# SN32F290 register map
Vendor: SONIX; File version: 2026.10.03
CPU: CM0 r0p0, little endian, 2 interrupt priority bits
Registers are 32-bit, read-write, reset 0x0 unless marked. A register's access mark holds for its fields unless they carry their own. Offsets are from the block's base; [hi:lo] are bit positions; {n}, {i} and the like mark numbered series; 'fields as' and 'values as' point back to an identical list.

## SN_EBI — External Bus Interface
Base 0x40036000
0x00 CTRL reset 0xF00000 (reset mask 0xFFFFFFF) — Offset:0x0 EBI Control Register
  [2n+48:n+24] BK8080MODE{n} (n=0..3) — Bank{n} 8080 Mode
    0=A1D16 (A1D16 mode); 1=A1D8 (A1D8 mode)
  [43:20] IDLETIME — Bus idle time
    0=No (No Idle time); {v}={v}T (Idle time={v}*PCLK) (v=1..15)
  [2n+32:n+16] ARDY{n}EN (n=0..3) — ARDY of bank {n} enable bit
    0=Disable bank {n} ARDY function; 1=Enable bank {n} ARDY function
  [2n+24:n+12] BC{n}EN (n=0..3) — Byte control of bank {n} enable bit
    0=Disable byte control of bank {n}; 1=Enable byte control of bank {n}
  [2n+16:n+8] BANK{n}EN (n=0..3) — EBI bank {n} enable bit
    0=Disable bank {n}; 1=Enable bank {n}
  [4n+1:2n] MODE{n} (n=0..3) — EBI bank {n} access mode
    0=AnD8 mode; 1=AnD16 mode; 2=AnD16ALE mode; 3=8080 mode
0x04 ALCTRL (reset mask 0xFFFF) — Offset:0x4 EBI Address Latch Control Register
  [8n+3:4n] AL{n} (n=0..3) — Bank {n} address length=AL{n}+16
    0=0000b (AL{n}=0); 1=0001b (AL{n}=1); 10=1010b (AL{n}=10); 11=1011b (AL{n}=10); 12=1100b (AL{n}=10); 13=1101b (AL{n}=10); 14=1110b (AL{n}=10); 15=1111b (AL{n}=10); 2=0010b (AL{n}=2); 3=0011b (AL{n}=3); 4=0100b (AL{n}=4); 5=0101b (AL{n}=5); 6=0110b (AL{n}=6); 7=0111b (AL{n}=7); 8=1000b (AL{n}=8); 9=1001b (AL{n}=9)
0x08 STATUS reset 0x10 (reset mask 0x111) — Offset:0x8 EBI Status Register
  [16:8] EBINSRST — EBI State machine reset
    0=Normal mode; 1=Reset EBI state machine
  [8:4] EBIARDY ro — EBI Asynchronous Ready status
    0=Inactive (EBI_ARDY is inactive); 1=Active (EBI_ARDY is active)
  [0] EBIBUSY ro
    0=Idle (EBI is idle); 1=Busy (EBI is busy)
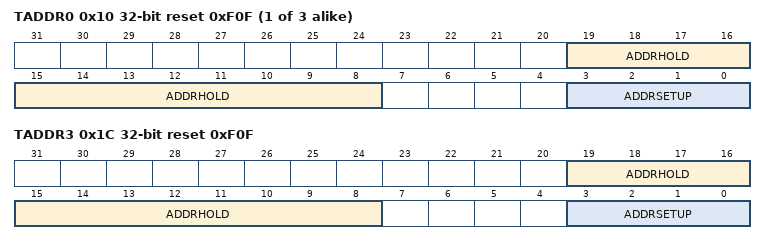
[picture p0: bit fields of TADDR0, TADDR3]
{0x10+4i} TADDR{i} reset 0xF0F (reset mask 0xF0F) (i=0..2) — Offset:{0x10+4i} EBI Address Timing Register {i}
  [19:8] ADDRHOLD — Address Hold time
    0=0000b (No Hold time); 1=0001b (1*PCLK); 10=1010b (10*PCLK); 11=1011b (11*PCLK); 12=1100b (12*PCLK); 13=1101b (13*PCLK); 14=1110b (14*PCLK); 15=1111b (15*PCLK); 2=0010b (2*PCLK); 3=0011b (3*PCLK); 4=0100b (4*PCLK); 5=0101b (5*PCLK); 6=0110b (6*PCLK); 7=0111b (7*PCLK); 8=1000b (8*PCLK); 9=1001b (9*PCLK)
  [3:0] ADDRSETUP — Address Setup time
    0=0000b (1*PCLK); 1=0001b (1*PCLK); 10=1010b (10*PCLK); 11=1011b (11*PCLK); 12=1100b (12*PCLK); 13=1101b (13*PCLK); 14=1110b (14*PCLK); 15=1111b (15*PCLK); 2=0010b (2*PCLK); 3=0011b (3*PCLK); 4=0100b (4*PCLK); 5=0101b (5*PCLK); 6=0110b (6*PCLK); 7=0111b (7*PCLK); 8=1000b (8*PCLK); 9=1001b (9*PCLK)
0x1C TADDR3 reset 0xF0F (reset mask 0xF0F) — Offset:0x1C EBI Address Timing Register 3
  [19:8] ADDRHOLD — Address Hold time
    0=0000b (No address hold time); 1=0001b (1*PCLK); 10=1010b (10*PCLK); 11=1011b (11*PCLK); 12=1100b (12*PCLK); 13=1101b (13*PCLK); 14=1110b (14*PCLK); 15=1111b (15*PCLK); 2=0010b (2*PCLK); 3=0011b (3*PCLK); 4=0100b (4*PCLK); 5=0101b (5*PCLK); 6=0110b (6*PCLK); 7=0111b (7*PCLK); 8=1000b (8*PCLK); 9=1001b (9*PCLK)
  [3:0] ADDRSETUP — Address Setup time
    values as TADDR0.ADDRSETUP
{0x20+4i} TREAD{i} reset 0xF3F0F (reset mask 0xF3F0F) (i=0..3) — Offset:{0x20+4i} EBI Read Timing Register {i}
  [35:16] RDHOLD — Read Hold time
    0=0000b (No read hold time); 1=0001b (1*PCLK); 10=1010b (10*PCLK); 11=1011b (11*PCLK); 12=1100b (12*PCLK); 13=1101b (13*PCLK); 14=1110b (14*PCLK); 15=1111b (15*PCLK); 2=0010b (2*PCLK); 3=0011b (3*PCLK); 4=0100b (4*PCLK); 5=0101b (5*PCLK); 6=0110b (6*PCLK); 7=0111b (7*PCLK); 8=1000b (8*PCLK); 9=1001b (9*PCLK)
  [21:8] RDSTRB — Read Strobe time
    0=000000b (1*PCLK); 1=000001b (1*PCLK); 10=001010b (10*PCLK); 11=001011b (11*PCLK); 12=001100b (12*PCLK); 13=001101b (13*PCLK); 14=001110b (14*PCLK); 15=001111b (15*PCLK); 16=010000b (16*PCLK); 17=010001b (17*PCLK); 18=010010b (18*PCLK); 19=010011b (19*PCLK); 2=000010b (2*PCLK); 20=010100b (20*PCLK); 21=010101b (21*PCLK); 22=010110b (22*PCLK); 23=010111b (23*PCLK); 24=011000b (24*PCLK); 25=011001b (25*PCLK); 26=011010b (26*PCLK); 27=011011b (27*PCLK); 28=011100b (28*PCLK); 29=011101b (29*PCLK); 3=000011b (3*PCLK); 30=011110b (30*PCLK); 31=011111b (31*PCLK); 32=100000b (32*PCLK); 33=100001b (33*PCLK); 34=100010b (34*PCLK); 35=100011b (35*PCLK); 36=100100b (36*PCLK); 37=100101b (37*PCLK); 38=100110b (38*PCLK); 39=100111b (39*PCLK); 4=000100b (4*PCLK); 40=101000b (40*PCLK); 41=101001b (41*PCLK); 42=101010b (42*PCLK); 43=101011b (43*PCLK); 44=101100b (44*PCLK); 45=101101b (45*PCLK); 46=101110b (46*PCLK); 47=101111b (47*PCLK); 48=110000b (48*PCLK); 49=110001b (49*PCLK); 5=000101b (5*PCLK); 50=110010b (50*PCLK); 51=110011b (51*PCLK); 52=110100b (52*PCLK); 53=110101b (53*PCLK); 54=110110b (54*PCLK); 55=110111b (55*PCLK); 56=111000b (56*PCLK); 57=111001b (57*PCLK); 58=111010b (58*PCLK); 59=111011b (59*PCLK); 6=000110b (6*PCLK); 60=111100b (60*PCLK); 61=111101b (61*PCLK); 62=111110b (62*PCLK); 63=111111b (63*PCLK); 7=000111b (7*PCLK); 8=001000b (8*PCLK); 9=001001b (9*PCLK)
  [3:0] RDSETUP — Read Setup time
    0=0000b (No read setup time); 1=0001b (1*PCLK); 10=1010b (10*PCLK); 11=1011b (11*PCLK); 12=1100b (12*PCLK); 13=1101b (13*PCLK); 14=1110b (14*PCLK); 15=1111b (15*PCLK); 2=0010b (2*PCLK); 3=0011b (3*PCLK); 4=0100b (4*PCLK); 5=0101b (5*PCLK); 6=0110b (6*PCLK); 7=0111b (7*PCLK); 8=1000b (8*PCLK); 9=1001b (9*PCLK)
{0x30+4i} TWRITE{i} reset 0xF3F0F (reset mask 0xF3F0F) (i=0..3) — Offset:{0x30+4i} EBI Write Timing Register {i}
  [35:16] WEHOLD — Write Hold time
    0=0000b (No write hold time); 1=0001b (1*PCLK); 10=1010b (10*PCLK); 11=1011b (11*PCLK); 12=1100b (12*PCLK); 13=1101b (13*PCLK); 14=1110b (14*PCLK); 15=1111b (15*PCLK); 2=0010b (2*PCLK); 3=0011b (3*PCLK); 4=0100b (4*PCLK); 5=0101b (5*PCLK); 6=0110b (6*PCLK); 7=0111b (7*PCLK); 8=1000b (8*PCLK); 9=1001b (9*PCLK)
  [21:8] WESTRB — Write Strobe time
    values as TREAD0.RDSTRB
  [3:0] WESETUP — Write Setup time
    0=0000b (No write setup time); 1=0001b (1*PCLK); 10=1010b (10*PCLK); 11=1011b (11*PCLK); 12=1100b (12*PCLK); 13=1101b (13*PCLK); 14=1110b (14*PCLK); 15=1111b (15*PCLK); 2=0010b (2*PCLK); 3=0011b (3*PCLK); 4=0100b (4*PCLK); 5=0101b (5*PCLK); 6=0110b (6*PCLK); 7=0111b (7*PCLK); 8=1000b (8*PCLK); 9=1001b (9*PCLK)
{0x40+4i} PR{i} (reset mask 0x3F) (i=0..3) — Offset:{0x40+4i} EBI Polarity Register {i}
  [10:5] UBLBPOL ro — Upper Byte and Lower Byte polarity
    0=Active Low (Upper byte and Lower byte are active low)
  [8:4] ARDYPOL — Asynchronous Ready polarity
    0=Active Low (ARDY is active low); 1=Active High (ARDY is active high)
  [6:3] ALEPOL ro — Address Latch polarity
    0=Active Low (ALE is active low)
  [4:2] WEPOL ro — Write Enable polarity
    0=Active Low (WE is active low)
  [2:1] OEPOL ro — Output Enable polarity
    0=Active Low (OE is active low)
  [0] CSPOL ro — Chip Select polarity
    0=Active Low (CS is active low)
0x50 IE (reset mask 0x3F) — Offset:0x50 EBI Interrupt Enable Register
  [10:5] DMATCIE — DMA transfer complete interrupt enable bit
    0=Disable DMATC interrupt; 1=Enable DMATC interrupt
  [8:4] DMAHTIE — DMA half-transfer interrupt enable bit
    0=Disable DMAHT interrupt; 1=Enable DMAHT interrupt
  [6:3] RWERREN — Interrupt for read/writer error enable bit
    0=Disable RWERR interrupt; 1=Enable RWERR interrupt
  [4:2] SMRSTEN — Interrupt for issuing a transaction during EBI state machine reset period enable bit
    0=Disable SMRST interrupt; 1=Enable SMRST interrupt
  [2:1] ACCDISEN — Interrupt for accessing the disabled bank enable bit
    0=Disable ACCDIS interrupt; 1=Enable ACCDIS interrupt
  [0] ARDYTOEN — EBI asynchronous ready time-out interrupt enable bit
    0=Disable ARDYTO interrupt; 1=Enable ARDYTO interrupt
0x54 RIS ro (reset mask 0x3F) — Offset:0x54 EBI Interrupt Flag Register
  [10:5] DMATCIF — DMA transfer complete flag
    0=No DMA transfer completed; 1=DMA Transfer completed (A transfer complete event occurs)
  [8:4] DMAHTIF — DMA half-transfer flag
    0=No event (No half-transfer event); 1=Half-transfer event (A half-transfer event occurs)
  [6:3] RWERRIF — EBI read/write error flag
    0=Not error (Not read/write error); 1=Error (Read/write error)
  [4:2] SMRSTIF — EBI state machine reset flag
    0=Not resetting the EBI state machine; 1=Resetting (EBI is resetting the state machine)
  [2:1] ACCDISIF — EBI accessing the disabled bank flag
    0=Not accessing the disabled bank; 1=Accessing (EBI is accessing the disabled bank)
  [0] ARDYTOIF — EBI asynchronous ready time-out flag
    0=Not timeout (ARDY Not Timeout); 1=Timeout (ARDY Timeout)
0x58 IC wo (reset mask 0x3F) — Offset:0x58 EBI Interrupt Clear Register
  [10:5] DMATCIC — Select DMA transfer complete flag to be cleared
    0=No effect; 1=Clear DMATCIF flag
  [8:4] DMAHTIC — Select DMA half-transfer flag to be cleared
    0=No effect; 1=Clear DMAHTIF flag
  [6:3] RWERRIC — Select RWERRIF flag to be cleared
    0=No effect; 1=Clear RWERRIF flag
  [4:2] SMRSTIC — Select SMRSTIF flag to be cleared
    0=No effect; 1=Clear SMRSTIF flag
  [2:1] ACCDISIC — Select ACCDISIF flag to be cleared
    0=No effect; 1=Clear ACCDISIF flag
  [0] ARDYTOIC — Select ARDYTOIF flag to be cleared
    0=No effect; 1=Clear ARDYIF flag
0x5C DMACTRL (reset mask 0xF) — Offset:0x5C EBI DMA Control Register
  [5:2] BANKSELECT — EBI Bank n select bits
    {v}=BANK {v} (EBI Bank {v}) (v=0..3)
  [2:1] SPISELECT — SPIn select bit
    0=SPI0; 1=SPI1
  [0] DMAEN — EBI DMA enable bit
    0=Disable EBI DMA; 1=Enable EBI DMA
0x64 DMACNT — Offset:0x64 DMA Number of data transfer register
  [27:0] CNT — Number of data to DMA RX count transfer
0x68 DMAHTCNT reset 0xFFFFFFF — Offset:0x68 EBI DMA Half-transfer Register
  [27:0] HTCNT — Number of data to DMA RX half count transfer
0x6C CURCNT ro — Offset:0x6C EBI DMA Current Transfer Data Counter Register
  [27:0] CURCNT — Number of data to DMA RX half count transfer
